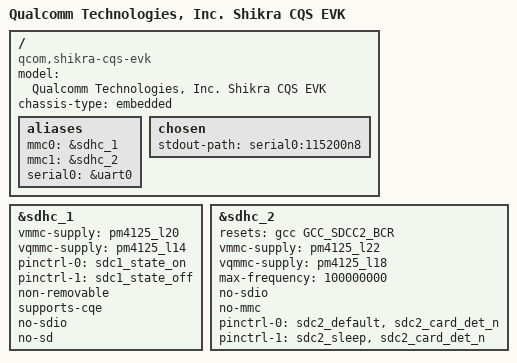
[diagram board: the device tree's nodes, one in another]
// SPDX-License-Identifier: BSD-3-Clause
/*
 * Copyright (c) Qualcomm Technologies, Inc. and/or its subsidiaries.
 */

/dts-v1/;

#include "shikra-cqm-som.dtsi"
#include "shikra-evk.dtsi"

/ {
	model = "Qualcomm Technologies, Inc. Shikra CQS EVK";
	compatible = "qcom,shikra-cqs-evk", "qcom,shikra-cqs-som", "qcom,shikra";
	chassis-type = "embedded";

	aliases {
		mmc0 = &sdhc_1;
		mmc1 = &sdhc_2;
		serial0 = &uart0;
	};

	chosen {
		stdout-path = "serial0:115200n8";
	};
};

&sdhc_1 {
	vmmc-supply = <&pm4125_l20>;
	vqmmc-supply = <&pm4125_l14>;

	pinctrl-0 = <&sdc1_state_on>;
	pinctrl-1 = <&sdc1_state_off>;
	pinctrl-names = "default", "sleep";

	non-removable;
	supports-cqe;
	no-sdio;
	no-sd;

	status = "okay";
};

&sdhc_2 {
	resets = <&gcc GCC_SDCC2_BCR>;
	vmmc-supply = <&pm4125_l22>;
	vqmmc-supply = <&pm4125_l18>;
	max-frequency = <100000000>;
	no-sdio;
	no-mmc;
	pinctrl-0 = <&sdc2_default &sdc2_card_det_n>;
	pinctrl-1 = <&sdc2_sleep &sdc2_card_det_n>;
	pinctrl-names = "default", "sleep";
	status = "okay";
};
